# ATmega128RFA1 register map
Vendor: Atmel; File version: 1.0
CPU: other r0p0, little endian, no MPU, no FPU, 4 interrupt priority bits
Registers are 8-bit, read-write, reset 0x0 unless marked. A register's access mark holds for its fields unless they carry their own. Offsets are from the block's base; [hi:lo] are bit positions; {n}, {i} and the like mark numbered series; <NAME> marks a mode.

## TRX24 — Low-Power 2.4 GHz Transceiver
Base 0x0080013C
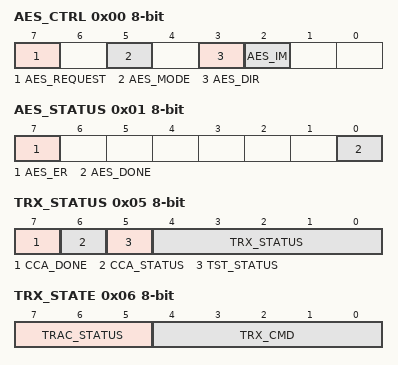
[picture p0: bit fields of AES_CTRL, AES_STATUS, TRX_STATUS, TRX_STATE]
0x00 AES_CTRL — AES Control Register
  [7] AES_REQUEST — Request AES Operation.
  [5] AES_MODE — Set AES Operation Mode
    0=AES_MODE_ECB (AES Mode is ECB (Electronic Code Book).); 1=AES_MODE_CBC (AES Mode is CBC (Cipher Block Chaining).)
  [3] AES_DIR — Set AES Operation Direction
    0=AES_DIR_ENC (AES operation is encryption.); 1=AES_DIR_DEC (AES operation is decryption.)
  [2] AES_IM — AES Interrupt Enable
0x01 AES_STATUS — AES Status Register (read-only for debugger)
  [7] AES_ER — AES Operation Finished with Error
  [0] AES_DONE — AES Operation Finished with Success
0x02 AES_STATE — AES Plain and Cipher Text Buffer Register
  [7:0] AES_STATE — AES Plain and Cipher Text Buffer
0x03 AES_KEY — AES Encryption and Decryption Key Buffer Register
  [7:0] AES_KEY — AES Encryption/Decryption Key Buffer
0x05 TRX_STATUS — Transceiver Status Register (read-only for debugger)
  [7] CCA_DONE — CCA Algorithm Status
    0=CCA_NOT_FIN (CCA calculation not finished); 1=CCA_FIN (CCA calculation finished)
  [6] CCA_STATUS — CCA Status Result
    0=CCA_BUSY (Channel indicated as busy.); 1=CCA_IDLE (Channel indicated as idle.)
  [5] TST_STATUS — Test mode status
    0=TST_DISABLED (Test mode is disabled.); 1=TST_ENABLED (Test mode is active.)
  [4:0] TRX_STATUS — Transceiver Main Status
    0=P_ON; 1=BUSY_RX; 2=BUSY_TX; 6=RX_ON; 8=TRX_OFF; 9=PLL_ON; 15=SLEEP; 17=BUSY_RX_AACK; 18=BUSY_TX_ARET; 22=RX_AACK_ON; 25=TX_ARET_ON; 31=STATE_TRANSITION_IN_PROGRESS
0x06 TRX_STATE — Transceiver State Control Register
  [7:5] TRAC_STATUS — Transaction Status
    0=TRAC_SUCCESS (SUCCESS (RX_AACK, TX_ARET)); 1=TRAC_SUCCESS_DATA_PENDING (SUCCESS_DATA_PENDING (TX_ARET)); 2=TRAC_SUCCESS_WAIT_FOR_ACK (SUCCESS_WAIT_FOR_ACK (RX_AACK)); 3=TRAC_CHANNEL_ACCESS_FAILURE (CHANNEL_ACCESS_FAILURE (TX_ARET)); 5=TRAC_NO_ACK (NO_ACK (TX_ARET)); 7=TRAC_INVALID (INVALID (RX_AACK, TX_ARET))
  [4:0] TRX_CMD — State Control Command
    0=CMD_NOP (NOP); 2=CMD_TX_START (TX_START); 3=CMD_FORCE_TRX_OFF (FORCE_TRX_OFF); 4=CMD_FORCE_PLL_ON (FORCE_PLL_ON); 6=CMD_RX_ON (RX_ON); 8=CMD_TRX_OFF (TRX_OFF); 9=CMD_PLL_ON (PLL_ON (TX_ON)); 22=CMD_RX_AACK_ON (RX_AACK_ON); 25=CMD_TX_ARET_ON (TX_ARET_ON)
0x07 TRX_CTRL_0 — Reserved
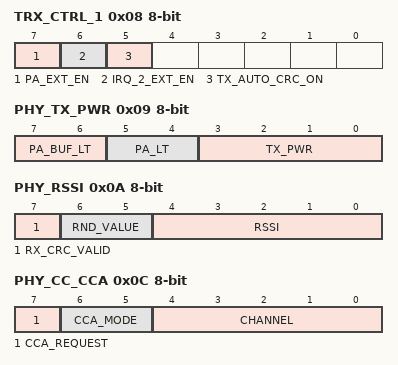
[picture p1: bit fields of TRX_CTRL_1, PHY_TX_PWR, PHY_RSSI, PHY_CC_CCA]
0x08 TRX_CTRL_1 — Transceiver Control Register 1
  [7] PA_EXT_EN — External PA support enable
  [6] IRQ_2_EXT_EN — Connect Frame Start IRQ to TC1
  [5] TX_AUTO_CRC_ON — Enable Automatic CRC Calculation
0x09 PHY_TX_PWR — Transceiver Transmit Power Control Register
  [7:6] PA_BUF_LT — Power Amplifier Buffer Lead Time
    0=PA_BUF_LT_0US (0 us); 1=PA_BUF_LT_2US (2 us); 2=PA_BUF_LT_4US (4 us); 3=PA_BUF_LT_6US (6 us)
  [5:4] PA_LT — Power Amplifier Lead Time
    0=PA_LT_2US (2 us); 1=PA_LT_4US (4 us); 2=PA_LT_6US (6 us); 3=PA_LT_8US (8 us)
  [3:0] TX_PWR — Transmit Power Setting
    0=3_0_DBM; 1=2_8_DBM; 2=2_3_DBM; 3=1_8_DBM; 4=1_3_DBM; 5=0_7_DBM; 6=0_0_DBM; {v}=_{v-6}_DBM (v=7..11); 12=_7_DBM; 13=_9_DBM; 14=_12_DBM; 15=_17_DBM
0x0A PHY_RSSI — Receiver Signal Strength Indicator Register (read-only for debugger)
  [7] RX_CRC_VALID — Received Frame CRC Status
    0=CRC_INVALID (CRC (FCS) not valid); 1=CRC_VALID (CRC (FCS) valid)
  [6:5] RND_VALUE — Random Value
  [4:0] RSSI — Receiver Signal Strength Indicator
    0=RSSI_MIN (Minimum RSSI value: P(RF) < -90 dBm); 1=RSSI_MIN_PLUS_3dB (P(RF) = RSSI_BASE_VAL+3 · (RSSI-1) [dBm]); 2=VAL_2; 28=RSSI_MAX (Maximum RSSI value: P(RF) ≥ -10 dBm)
0x0B PHY_ED_LEVEL — Transceiver Energy Detection Level Register (read-only for debugger)
  [7:0] ED_LEVEL — Energy Detection Level
    0=ED_MIN (Minimum result of last ED measurement); 1=ED_MIN_PLUS_1dB (P(RF) = RSSI_BASE_VAL+ED [dBm]); 2=VAL_0x02; 84=ED_MAX (Maximum result of last ED measurement); 255=ED_RESET (Reset value)
0x0C PHY_CC_CCA — Transceiver Clear Channel Assessment (CCA) Control Register
  [7] CCA_REQUEST — Manual CCA Measurement Request
  [6:5] CCA_MODE — Select CCA Measurement Mode
    0=CCA_CS_OR_ED (Mode 3a, Carrier sense OR energy above threshold); 1=CCA_ED (Mode 1, Energy above threshold); 2=CCA_CS (Mode 2, Carrier sense only); 3=CCA_CS_AND_ED (Mode 3b, Carrier sense AND energy above threshold)
  [4:0] CHANNEL — RX/TX Channel Selection
    11=F_2405MHZ (2405 MHz); 12=F_2410MHZ (2410 MHz); 13=F_2415MHZ (2415 MHz); 14=F_2420MHZ (2420 MHz); 15=F_2425MHZ (2425 MHz); 16=F_2430MHZ (2430 MHz); 17=F_2435MHZ (2435 MHz); 18=F_2440MHZ (2440 MHz); 19=F_2445MHZ (2445 MHz); 20=F_2450MHZ (2450 MHz); 21=F_2455MHZ (2455 MHz); 22=F_2460MHZ (2460 MHz); 23=F_2465MHZ (2465 MHz); 24=F_2470MHZ (2470 MHz); 25=F_2475MHZ (2475 MHz); 26=F_2480MHZ (2480 MHz)
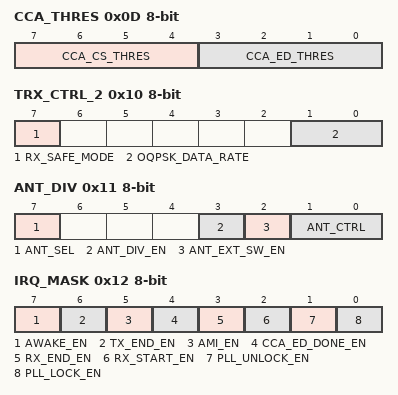
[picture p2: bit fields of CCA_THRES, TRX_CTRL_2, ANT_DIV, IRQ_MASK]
0x0D CCA_THRES — Transceiver CCA Threshold Setting Register
  [7:4] CCA_CS_THRES — CS Threshold Level for CCA Measurement
  [3:0] CCA_ED_THRES — ED Threshold Level for CCA Measurement
0x0E RX_CTRL — Transceiver Receive Control Register
  [3:0] PDT_THRES — Receiver Sensitivity Control
    3=PDT_THRES_ANT_DIV_ON (Recommended correlator threshold for Antenna Diversity operation); 7=PDT_THRES_ANT_DIV_OFF (Reset value, to be used if Antenna Diversity algorithm is disabled)
0x0F SFD_VALUE — Start of Frame Delimiter Value Register
  [7:0] SFD_VALUE — Start of Frame Delimiter Value
    167=IEEE_SFD (IEEE 802.15.4 compliant value of the SFD)
0x10 TRX_CTRL_2 — Transceiver Control Register 2
  [7] RX_SAFE_MODE
  [1:0] OQPSK_DATA_RATE — Data Rate Selection
    0=RATE_250KB (250 kb/s (IEEE 802.15.4 compliant)); 1=RATE_500KB (500 kb/s); 2=RATE_1000KB (1000 kb/s); 3=RATE_2000KB (2000 kb/s)
0x11 ANT_DIV — Antenna Diversity Control Register
  [7] ANT_SEL — Antenna Diversity Antenna Status
    0=ANTENNA_0; 1=ANTENNA_1
  [3] ANT_DIV_EN — Enable Antenna Diversity
    0=ANTENNA_DIVERSITY_ALGORITHM_DISABLED; 1=ANTENNA_DIVERSITY_ALGORITHM_ENABLED
  [2] ANT_EXT_SW_EN — Enable External Antenna Switch Control
    0=ANT_DIV_EXT_SW_DIS (Antenna Diversity RF switch control disabled); 1=ANT_DIV_EXT_SW_EN (Antenna Diversity RF switch control enabled)
  [1:0] ANT_CTRL — Static Antenna Diversity Switch Control
    1=ANT_1 (Antenna 1: DIG1=H, DIG2=L); 2=ANT_0 (Antenna 0: DIG1=L, DIG2=H); 3=ANT_RESET (Default value for ANT_EXT_SW_EN=0; Mandatory setting for applications not using Antenna Diversity)
0x12 IRQ_MASK — Transceiver Interrupt Enable Register
  [7] AWAKE_EN — Awake Interrupt Enable
  [6] TX_END_EN — TX_END Interrupt Enable
  [5] AMI_EN — Address Match Interrupt Enable
  [4] CCA_ED_DONE_EN — End of ED Measurement Interrupt Enable
  [3] RX_END_EN — RX_END Interrupt Enable
  [2] RX_START_EN — RX_START Interrupt Enable
  [1] PLL_UNLOCK_EN — PLL Unlock Interrupt Enable
  [0] PLL_LOCK_EN — PLL Lock Interrupt Enable
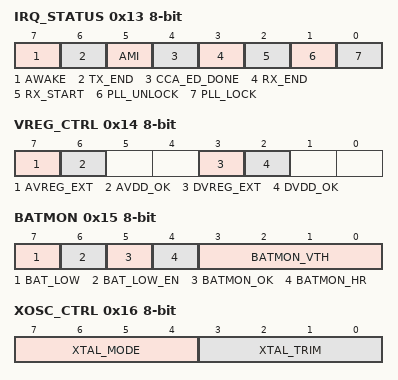
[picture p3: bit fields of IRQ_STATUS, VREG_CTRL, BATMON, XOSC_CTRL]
0x13 IRQ_STATUS — Transceiver Interrupt Status Register
  [7] AWAKE — Awake Interrupt Status
  [6] TX_END — TX_END Interrupt Status
  [5] AMI — Address Match Interrupt Status
  [4] CCA_ED_DONE — End of ED Measurement Interrupt Status
  [3] RX_END — RX_END Interrupt Status
  [2] RX_START — RX_START Interrupt Status
  [1] PLL_UNLOCK — PLL Unlock Interrupt Status
  [0] PLL_LOCK — PLL Lock Interrupt Status
0x14 VREG_CTRL — Voltage Regulator Control and Status Register
  [7] AVREG_EXT — Use External AVDD Regulator
    0=AVDD_INT (Internal AVDD voltage regulator for the analog section is enabled.); 1=AVDD_EXT (Internal AVDD voltage regulator is disabled; use external regulated 1.8V supply voltage for the analog section.)
  [6] AVDD_OK — AVDD Supply Voltage Valid
    0=ANALOG_VOLTAGE_REGULATOR_DISABLED_OR_SUPPLY_VOLTAGE_NOT_STABLE; 1=ANALOG_SUPPLY_VOLTAGE_HAS_SETTLED
  [3] DVREG_EXT — Use External DVDD Regulator
    0=DVDD_INT (Internal DVDD voltage regulator for the digital section is enabled.); 1=DVDD_EXT (Internal DVDD voltage regulator is disabled; use external regulated 1.8V supply voltage for the digital section.)
  [2] DVDD_OK — DVDD Supply Voltage Valid
    0=DIGITAL_VOLTAGE_REGULATOR_DISABLED_OR_SUPPLY_VOLTAGE_NOT_STABLE; 1=DIGITAL_SUPPLY_VOLTAGE_HAS_SETTLED
0x15 BATMON — Battery Monitor Control and Status Register
  [7] BAT_LOW — Battery Monitor Interrupt Status
  [6] BAT_LOW_EN — Battery Monitor Interrupt Enable
  [5] BATMON_OK — Battery Monitor Status
    0=THE_BATTERY_VOLTAGE_IS_BELOW_THE_THRESHOLD; 1=THE_BATTERY_VOLTAGE_IS_ABOVE_THE_THRESHOLD
  [4] BATMON_HR — Battery Monitor Voltage Range
    0=BATMON_HR_DIS (Enables the low range, see BATMON_VTH); 1=BATMON_HR_EN (Enables the high range, see BATMON_VTH)
  [3:0] BATMON_VTH — Battery Monitor Threshold Voltage
    0=2_550V_BATMON_HR_1_1_70V_BATMON_HR_0; 1=2_625V_BATMON_HR_1_1_75V_BATMON_HR_0; 2=2_700V_BATMON_HR_1_1_80V_BATMON_HR_0; 3=2_775V_BATMON_HR_1_1_85V_BATMON_HR_0; 4=2_850V_BATMON_HR_1_1_90V_BATMON_HR_0; 5=2_925V_BATMON_HR_1_1_95V_BATMON_HR_0; 6=3_000V_BATMON_HR_1_2_00V_BATMON_HR_0; 7=3_075V_BATMON_HR_1_2_05V_BATMON_HR_0; 8=3_150V_BATMON_HR_1_2_10V_BATMON_HR_0; 9=3_225V_BATMON_HR_1_2_15V_BATMON_HR_0; 10=3_300V_BATMON_HR_1_2_20V_BATMON_HR_0; 11=3_375V_BATMON_HR_1_2_25V_BATMON_HR_0; 12=3_450V_BATMON_HR_1_2_30V_BATMON_HR_0; 13=3_525V_BATMON_HR_1_2_35V_BATMON_HR_0; 14=3_600V_BATMON_HR_1_2_40V_BATMON_HR_0; 15=3_675V_BATMON_HR_1_2_45V_BATMON_HR_0
0x16 XOSC_CTRL — Crystal Oscillator Control Register
  [7:4] XTAL_MODE — Crystal Oscillator Operating Mode
    4=INTERNAL_CRYSTAL_OSCILLATOR_DISABLED_USE_EXTERNAL_REFERENCE_FREQUENCY; 15=INTERNAL_CRYSTAL_OSCILLATOR_ENABLED_AMPLITUDE_REGULATION_OF_OSCILLATION_ENABLED
  [3:0] XTAL_TRIM — Crystal Oscillator Load Capacitance Trimming
    0=XTAL_TRIM_MIN (0.0 pF, trimming capacitors disconnected); 1=0.3 pF, trimming capacitor switched on; 2=VAL_0x2; 15=XTAL_TRIM_MAX (4.5 pF, trimming capacitor switched on)
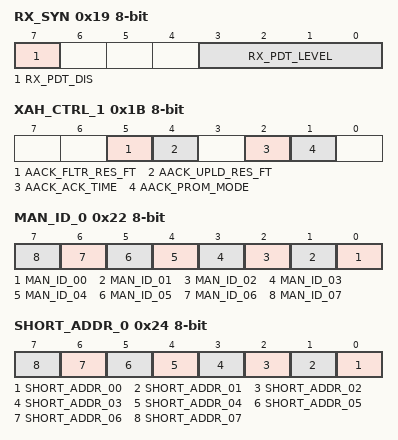
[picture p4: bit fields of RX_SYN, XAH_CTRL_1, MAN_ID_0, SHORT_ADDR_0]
0x19 RX_SYN — Transceiver Receiver Sensitivity Control Register
  [7] RX_PDT_DIS — Prevent Frame Reception
  [3:0] RX_PDT_LEVEL — Reduce Receiver Sensitivity
    0=RX_PDT_LEVEL_MIN (RX_THRES ≤ RSSI_BASE_VAL (Reset value); RSSI value not considered); 1=RX_THRES > RSSI_BASE_VAL + 0 · 3; RSSI > -90 dBm; 2=VAL_0x2; 14=RX_THRES > RSSI_BASE_VAL + 13 · 3; RSSI > -51 dBm; 15=RX_PDT_LEVEL_MAX (RX_THRES > RSSI_BASE_VAL + 14 · 3; RSSI > -48 dBm)
0x1B XAH_CTRL_1 — Transceiver Acknowledgment Frame Control Register 1
  [5] AACK_FLTR_RES_FT — Filter Reserved Frames
  [4] AACK_UPLD_RES_FT — Process Reserved Frames
  [2] AACK_ACK_TIME — Reduce Acknowledgment Time
    0=AACK_ACK_TIME_12_SYM (12 symbols acknowledgment time); 1=AACK_ACK_TIME_2_SYM (2 symbols acknowledgment time)
  [1] AACK_PROM_MODE — Enable Promiscuous Mode
0x1C FTN_CTRL — Transceiver Filter Tuning Control Register
  [7] FTN_START — Start Calibration Loop of Filter Tuning Network
0x1E PLL_CF — Transceiver Center Frequency Calibration Control Register
  [7] PLL_CF_START — Start Center Frequency Calibration
0x1F PLL_DCU — Transceiver Delay Cell Calibration Control Register
  [7] PLL_DCU_START — Start Delay Cell Calibration
0x20 PART_NUM — Device Identification Register (Part Number) (read-only for debugger)
  [7:0] PART_NUM — Part Number
    131=P_ATmega128RFA1 (ATmega128RFA1 part number)
0x21 VERSION_NUM — Device Identification Register (Version Number) (read-only for debugger)
  [7:0] VERSION_NUM — Version Number
    2=REV_A (Revision A); 3=REV_B (Revision B)
0x22 MAN_ID_0 — Device Identification Register (Manufacture ID Low Byte) (read-only for debugger)
  [n] MAN_ID_{n:02} (n=0..7) — Manufacturer ID (Low Byte)
0x23 MAN_ID_1 — Device Identification Register (Manufacture ID High Byte) (read-only for debugger)
  [7:0] MAN_ID_ — Manufacturer ID (High Byte)
    0=ATMEL_BYTE_1 (Atmel JEDEC manufacturer ID, bits [15:8] of 32 bit manufacturer ID: 00 00 00 1F)
0x24 SHORT_ADDR_0 — Transceiver MAC Short Address Register (Low Byte)
  [n] SHORT_ADDR_{n:02} (n=0..7) — MAC Short Address
0x25 SHORT_ADDR_1 — Transceiver MAC Short Address Register (High Byte)
  [7:0] SHORT_ADDR_ — MAC Short Address
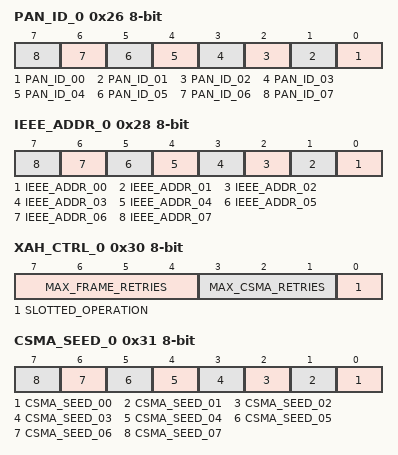
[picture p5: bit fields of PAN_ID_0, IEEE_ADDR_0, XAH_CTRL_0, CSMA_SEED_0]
0x26 PAN_ID_0 — Transceiver Personal Area Network ID Register (Low Byte)
  [n] PAN_ID_{n:02} (n=0..7) — MAC Personal Area Network ID
0x27 PAN_ID_1 — Transceiver Personal Area Network ID Register (High Byte)
  [7:0] PAN_ID_ — MAC Personal Area Network ID
0x28 IEEE_ADDR_0 — Transceiver MAC IEEE Address Register 0
  [n] IEEE_ADDR_{n:02} (n=0..7) — MAC IEEE Address
{0x28+i} IEEE_ADDR_{i} (i=1..7) — Transceiver MAC IEEE Address Register {i}
  [7:0] IEEE_ADDR_ — MAC IEEE Address
0x30 XAH_CTRL_0 — Transceiver Extended Operating Mode Control Register
  [7:4] MAX_FRAME_RETRIES — Maximum Number of Frame Re-transmission Attempts
    0=RETRANSMISSION_OF_FRAME_IS_NOT_ATTEMPTED; 1=RETRANSMISSION_OF_FRAME_IS_ATTEMPTED_ONCE; 15=RETRANSMISSION_OF_FRAME_IS_ATTEMPTED_15_TIMES
  [3:1] MAX_CSMA_RETRIES — Maximum Number of CSMA-CA Procedure Repetition Attempts
    0=NO_REPETITION_OF_CSMA_CA_PROCEDURE; 1=ONE_REPETITION_OF_CSMA_CA_PROCEDURE; 5=FIVE_REPETITIONS_HIGHEST_IEEE_802_15_4_COMPLIANT_VALUE; 7=IMMEDIATE_FRAME_RE_TRANSMISSION_WITHOUT_PERFORMING_CSMA_CA
  [0] SLOTTED_OPERATION — Set Slotted Acknowledgment
    0=SLOTTED_OP_DIS (The radio transceiver operates in unslotted mode. An acknowledgment frame is automatically sent if requested.); 1=SLOTTED_OP_EN (The transmission of an acknowledgment frame has to be controlled by the microcontroller.)
0x31 CSMA_SEED_0 — Transceiver CSMA-CA Random Number Generator Seed Register
  [n] CSMA_SEED_{n:02} (n=0..7) — Seed Value for CSMA Random Number Generator
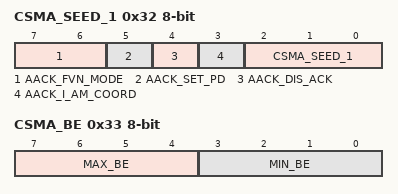
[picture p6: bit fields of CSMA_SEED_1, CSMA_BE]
0x32 CSMA_SEED_1 — Transceiver Acknowledgment Frame Control Register 2
  [7:6] AACK_FVN_MODE — Acknowledgment Frame Filter Mode
    0=ACKNOWLEDGE_FRAMES_WITH_VERSION_NUMBER_0; 1=ACKNOWLEDGE_FRAMES_WITH_VERSION_NUMBER_0_OR_1; 2=ACKNOWLEDGE_FRAMES_WITH_VERSION_NUMBER_0_OR_1_OR_2; 3=ACKNOWLEDGE_FRAMES_INDEPENDENT_OF_FRAME_VERSION_NUMBER
  [5] AACK_SET_PD — Set Frame Pending Sub-field
  [4] AACK_DIS_ACK — Disable Acknowledgment Frame Transmission
  [3] AACK_I_AM_COORD — Set Personal Area Network Coordinator
  [2:0] CSMA_SEED_1 — Seed Value for CSMA Random Number Generator
0x33 CSMA_BE — Transceiver CSMA-CA Back-off Exponent Control Register
  [7:4] MAX_BE — Maximum Back-off Exponent
    2=THIS_VALUE_IS_NOT_VALID_FOR_THE_MAXIMUM_BACK_OFF_EXPONENT; 3=MINIMUM_IEEE_COMPLIANT_VALUE_FOR_THE_MAXIMUM_BACK_OFF_EXPONENT; 8=MAXIMUM_IEEE_COMPLIANT_VALUE_FOR_THE_MAXIMUM_BACK_OFF_EXPONENT
  [3:0] MIN_BE — Minimum Back-off Exponent
    0=MINIMUM_VALUE_OF_MINIMUM_BACK_OFF_EXPONENT; 8=MAXIMUM_VALUE_OF_MINIMUM_BACK_OFF_EXPONENT_MIN_BE_MUST_BE_SMALLER_OR_EQUAL_TO_MAX_BE
0x3A TST_CTRL_DIGI — Transceiver Digital Test Control Register
  [3:0] TST_CTRL_DIG — Digital Test Controller Register
    0=NORMAL_NO_TEST_IS_ACTIVE; 15=TST_CONT_TX_CONTINUOUS_TRANSMIT
0x3F TST_RX_LENGTH — Transceiver Received Frame Length Register
  [7:0] RX_LENGTH — Received Frame Length
0x44 TRXFBST — Start of frame buffer
0xC3 TRXFBEND — End of frame buffer
